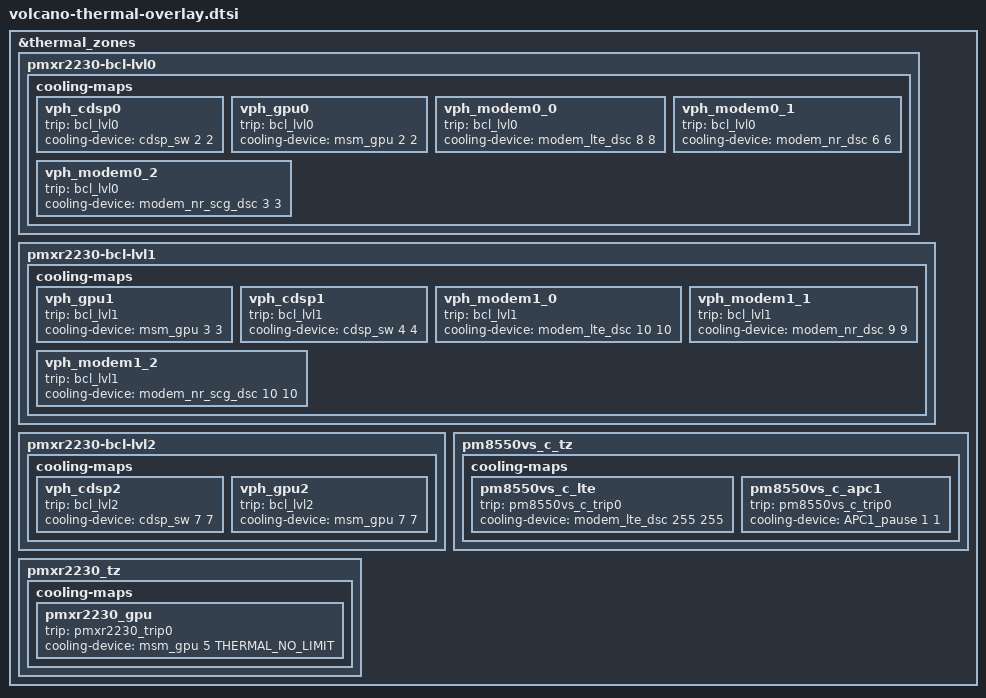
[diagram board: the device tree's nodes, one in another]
#include <dt-bindings/thermal/thermal_qti.h>

&thermal_zones {
	pmxr2230-bcl-lvl0 {
		cooling-maps {
			vph_cdsp0 {
				trip = <&bcl_lvl0>;
				cooling-device = <&cdsp_sw 2 2>;
			};

			vph_gpu0 {
				trip = <&bcl_lvl0>;
				cooling-device = <&msm_gpu 2 2>;
			};

			vph_modem0_0 {
				trip = <&bcl_lvl0>;
				cooling-device = <&modem_lte_dsc 8 8>;
			};

			vph_modem0_1 {
				trip = <&bcl_lvl0>;
				cooling-device = <&modem_nr_dsc 6 6>;
			};

			vph_modem0_2 {
				trip = <&bcl_lvl0>;
				cooling-device = <&modem_nr_scg_dsc 3 3>;
			};
		};
	};

	pmxr2230-bcl-lvl1 {
		cooling-maps {
			vph_gpu1 {
				trip = <&bcl_lvl1>;
				cooling-device = <&msm_gpu 3 3>;
			};

			vph_cdsp1 {
				trip = <&bcl_lvl1>;
				cooling-device = <&cdsp_sw 4 4>;
			};

			vph_modem1_0 {
				trip = <&bcl_lvl1>;
				cooling-device = <&modem_lte_dsc 10 10>;
			};

			vph_modem1_1 {
				trip = <&bcl_lvl1>;
				cooling-device = <&modem_nr_dsc 9 9>;
			};

			vph_modem1_2 {
				trip = <&bcl_lvl1>;
				cooling-device = <&modem_nr_scg_dsc 10 10>;
			};
		};
	};

	pmxr2230-bcl-lvl2 {
		cooling-maps {
			vph_cdsp2 {
				trip = <&bcl_lvl2>;
				cooling-device = <&cdsp_sw 7 7>;
			};

			vph_gpu2 {
				trip = <&bcl_lvl2>;
				cooling-device = <&msm_gpu 7 7>;
			};
		};
	};

	pm8550vs_c_tz {
		cooling-maps {
			pm8550vs_c_lte {
				trip = <&pm8550vs_c_trip0>;
				cooling-device = <&modem_lte_dsc 255 255>;
			};

			pm8550vs_c_apc1 {
				trip = <&pm8550vs_c_trip0>;
				cooling-device = <&APC1_pause 1 1>;
			};
		};
	};

	pmxr2230_tz {
		cooling-maps {
			pmxr2230_gpu {
				trip = <&pmxr2230_trip0>;
				cooling-device = <&msm_gpu 5 THERMAL_NO_LIMIT>;
			};
		};
	};

};
